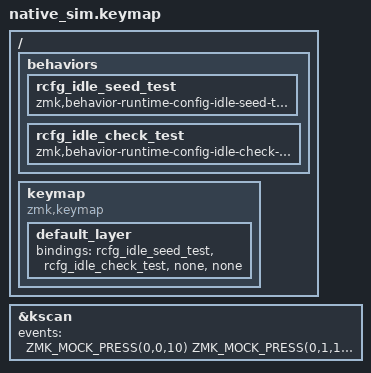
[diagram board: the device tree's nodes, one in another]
#include <dt-bindings/zmk/keys.h>
#include <behaviors.dtsi>
#include <dt-bindings/zmk/kscan_mock.h>

/ {
    behaviors {
        rcfg_idle_seed_test: rcfg_idle_seed_test {
            compatible = "zmk,behavior-runtime-config-idle-seed-test";
            #binding-cells = <0>;
        };

        rcfg_idle_check_test: rcfg_idle_check_test {
            compatible = "zmk,behavior-runtime-config-idle-check-test";
            #binding-cells = <0>;
        };
    };

    keymap {
        compatible = "zmk,keymap";

        default_layer {
            bindings = <&rcfg_idle_seed_test &rcfg_idle_check_test &none &none>;
        };
    };
};

/*
 * CONFIG_ZMK_RUNTIME_CONFIG_ACTIVATION_IDLE_MS defaults to 25ms.
 *
 * kscan_mock.c's own msec field is a gotcha, confirmed by reading the
 * driver directly: kscan_mock_work_handler fires an event using
 * cfg->events[event_index], then reschedules using that *same*,
 * not-yet-incremented index before finally incrementing it - so an
 * event's msec value actually governs the gap *after* it fires (before
 * the next one), not the gap before itself. The delay that matters here
 * has to sit on the seed's release (the event that starts the idle
 * countdown), not on the check press that observes the result.
 *
 *  t=10  seed press    -> requests activation of generation 1, but
 *                         position 0 is still down: not safe, not
 *                         scheduled yet.
 *  t=20  check press   -> position 0 is *still* down (its own release is
 *                         the next event): pressed_key_count=2, not
 *                         active, not yet scheduled.
 *  t=30  check release -> position 0 still down alone: still not safe.
 *  t=40  seed release  -> nothing held now: safe, schedules activation
 *                         for t=40+50=90 (its own msec field, per the
 *                         gotcha above).
 *  t=90  check press   -> right at the deadline, comfortably past the
 *                         25ms threshold: activation already completed
 *                         asynchronously, pressed_key_count=1 (this
 *                         press's own).
 */
&kscan {
    events = <
        ZMK_MOCK_PRESS(0,0,10)
        ZMK_MOCK_PRESS(0,1,10)
        ZMK_MOCK_RELEASE(0,1,10)
        ZMK_MOCK_RELEASE(0,0,50)
        ZMK_MOCK_PRESS(0,1,10)
        ZMK_MOCK_RELEASE(0,1,10)
    >;
};
